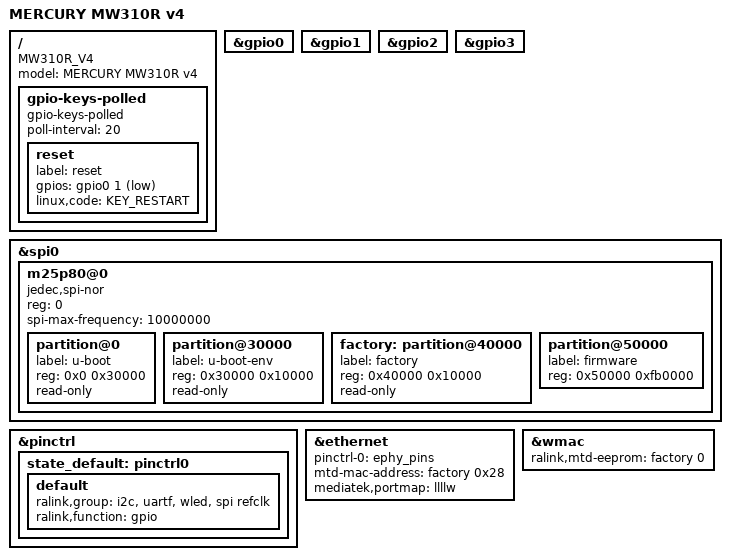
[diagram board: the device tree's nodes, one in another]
/dts-v1/;

#include "mt7620a.dtsi"

#include <dt-bindings/input/input.h>

/ {
	compatible = "MW310R_V4", "ralink,mt7620a-soc";
	model = "MERCURY MW310R v4";

	gpio-keys-polled {
		compatible = "gpio-keys-polled";
		#address-cells = <1>;
		#size-cells = <0>;
		poll-interval = <20>;
		reset {
			label = "reset";
			gpios = <&gpio0 1 1>;
			linux,code = <KEY_RESTART>;
		};
	};
};

&gpio0 {
	status = "okay";
};

&gpio1 {
	status = "okay";
};

&gpio2 {
	status = "okay";
};

&gpio3 {
	status = "okay";
};

&spi0 {
	status = "okay";

	m25p80@0 {
		#address-cells = <1>;
		#size-cells = <1>;
		compatible = "jedec,spi-nor";
		reg = <0>;
		spi-max-frequency = <10000000>;

		partition@0 {
			label = "u-boot";
			reg = <0x0 0x30000>;
			read-only;
		};

		partition@30000 {
			label = "u-boot-env";
			reg = <0x30000 0x10000>;
			read-only;
		};

		factory: partition@40000 {
			label = "factory";
			reg = <0x40000 0x10000>;
			read-only;
		};

		partition@50000 {
			label = "firmware";
			reg = <0x50000 0xfb0000>;
		};
	};
};

&pinctrl {
	state_default: pinctrl0 {
		default {
			ralink,group = "i2c", "uartf", "wled", "spi refclk";
			ralink,function = "gpio";
		};
	};
};

&ethernet {
	pinctrl-names = "default";
	pinctrl-0 = <&ephy_pins>;
	mtd-mac-address = <&factory 0x28>;
	mediatek,portmap = "llllw";
};

&wmac {
	ralink,mtd-eeprom = <&factory 0>;
};
